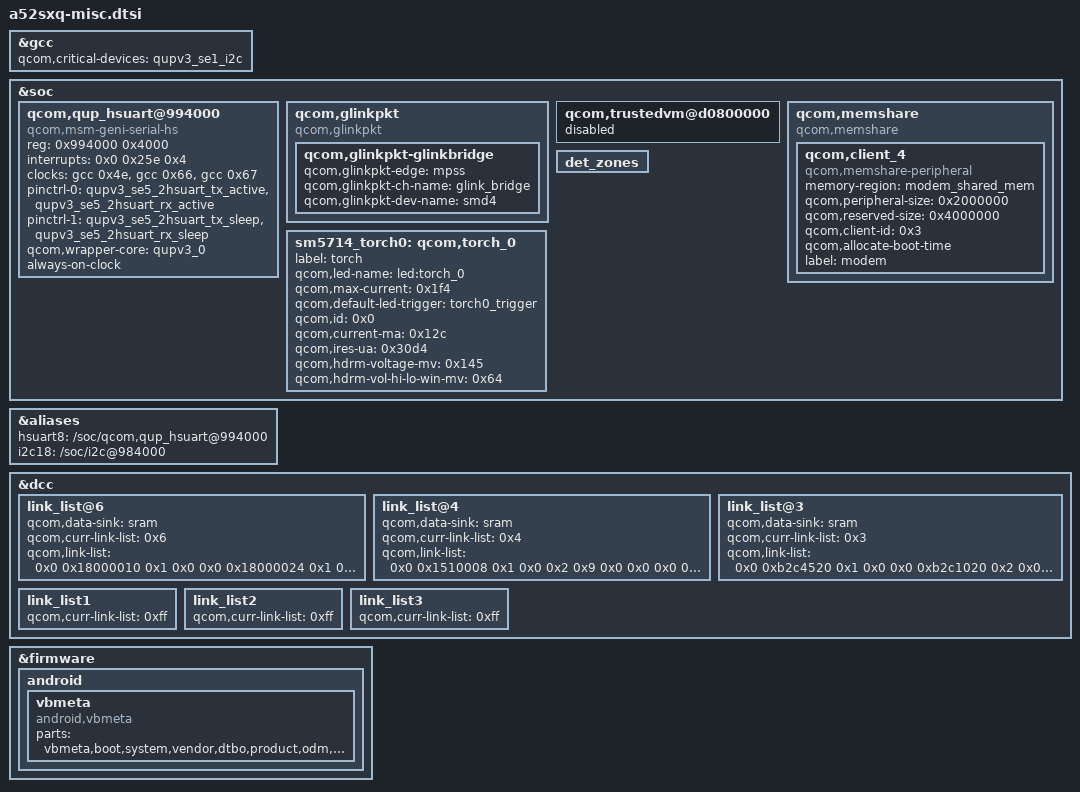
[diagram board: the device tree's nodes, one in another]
// SPDX-License-Identifier: GPL-2.0
/*
 * a52sxq board description for the Qualcomm 6.12 yupik base: misc
 * GENERATED by tools/gen.py from the phone's stock dtbo (5.4 bindings, values verbatim).
 * Do not edit: hand-written 6.12 changes live in a52sxq-bsp612-fixups.dtsi.
 */

&gcc {
	qcom,critical-devices = <&qupv3_se1_i2c>;
};

&soc {

	qcom,qup_hsuart@994000 {
		compatible = "qcom,msm-geni-serial-hs";
		reg = <0x994000 0x4000>;
		reg-names = "se_phys";
		interrupts = <0x0 0x25e 0x4>;
		clock-names = "se-clk", "m-ahb", "s-ahb";
		clocks = <&gcc 0x4e &gcc 0x66 &gcc 0x67>;
		pinctrl-names = "default", "sleep";
		pinctrl-0 = <&qupv3_se5_2hsuart_tx_active &qupv3_se5_2hsuart_rx_active>;
		pinctrl-1 = <&qupv3_se5_2hsuart_tx_sleep &qupv3_se5_2hsuart_rx_sleep>;
		qcom,wrapper-core = <&qupv3_0>;
		always-on-clock;
		status = "ok";
	};

	qcom,glinkpkt {
		compatible = "qcom,glinkpkt";

		qcom,glinkpkt-glinkbridge {
			qcom,glinkpkt-edge = "mpss";
			qcom,glinkpkt-ch-name = "glink_bridge";
			qcom,glinkpkt-dev-name = "smd4";
		};
	};

	qcom,trustedvm@d0800000 {
		status = "disabled";
	};

	qcom,memshare {
		compatible = "qcom,memshare";

		qcom,client_4 {
			compatible = "qcom,memshare-peripheral";
			memory-region = <&modem_shared_mem>;
			qcom,peripheral-size = <0x2000000>;
			qcom,reserved-size = <0x4000000>;
			qcom,client-id = <0x3>;
			qcom,allocate-boot-time;
			label = "modem";
		};
	};

	det_zones: det_zones {
		#list-det-cells = <0x2>;
	};

	sm5714_torch0: qcom,torch_0 {
		label = "torch";
		qcom,led-name = "led:torch_0";
		qcom,max-current = <0x1f4>;
		qcom,default-led-trigger = "torch0_trigger";
		qcom,id = <0x0>;
		qcom,current-ma = <0x12c>;
		qcom,ires-ua = <0x30d4>;
		qcom,hdrm-voltage-mv = <0x145>;
		qcom,hdrm-vol-hi-lo-win-mv = <0x64>;
	};
};

&aliases {
	hsuart8 = "/soc/qcom,qup_hsuart@994000";
	i2c18 = "/soc/i2c@984000";
};

&dcc {

	link_list@6 {
		qcom,data-sink = "sram";
		qcom,curr-link-list = <0x6>;
		qcom,link-list = <0x0 0x18000010 0x1 0x0 0x0 0x18000024 0x1 0x0 0x0 0x18000038 0x6 0x0 0x0 0x18010010 0x1 0x0 0x0 0x18010024 0x1 0x0 0x0 0x18010038 0x6 0x0 0x0 0x18020010 0x1 0x0 0x0 0x18020024 0x1 0x0 0x0 0x18020038 0x6 0x0 0x0 0x18030010 0x1 0x0 0x0 0x18030024 0x1 0x0 0x0 0x18030038 0x6 0x0 0x0 0x18040010 0x1 0x0 0x0 0x18040024 0x1 0x0 0x0 0x18040038 0x6 0x0 0x0 0x18050010 0x1 0x0 0x0 0x18050024 0x1 0x0 0x0 0x18050038 0x6 0x0 0x0 0x18060010 0x1 0x0 0x0 0x18060024 0x1 0x0 0x0 0x18060038 0x6 0x0 0x0 0x18070010 0x1 0x0 0x0 0x18070024 0x1 0x0 0x0 0x18070038 0x6 0x0 0x0 0x18080010 0x1 0x0 0x0 0x18080024 0x1 0x0 0x0 0x18080038 0x6 0x0 0x0 0x1808006c 0x5 0x0 0x0 0x18080084 0x1 0x0 0x0 0x180800f4 0x1 0x0 0x0 0x180800f8 0x1 0x0 0x0 0x180800fc 0x1 0x0 0x0 0x18080100 0xc 0x0 0x0 0x18080130 0x3 0x0 0x0 0x18080158 0x1 0x0 0x0 0x1808015c 0x1 0x0 0x0 0x18080160 0x1 0x0 0x0 0x18080164 0x1 0x0 0x0 0x18080168 0x1 0x0 0x0 0x18080170 0x1 0x0 0x0 0x18080174 0x1 0x0 0x0 0x18080188 0x1 0x0 0x0 0x1808018c 0x1 0x0 0x0 0x18080190 0x1 0x0 0x0 0x18080194 0x1 0x0 0x0 0x18080198 0x1 0x0 0x0 0x180801ac 0x1 0x0 0x0 0x180801b0 0x4 0x0 0x0 0x180801c0 0x1 0x0 0x0 0x180801c8 0x1 0x0 0x0 0x180801f0 0x1 0x0 0x0 0x18598020 0x1 0x0 0x0 0x1859001c 0x1 0x0 0x0 0x18590020 0x1 0x0 0x0 0x1859002c 0x1 0x0 0x0 0x18590064 0x1 0x0 0x0 0x18590068 0x1 0x0 0x0 0x1859006c 0x1 0x0 0x0 0x18590070 0x3 0x0 0x0 0x1859008c 0x1 0x0 0x0 0x185900dc 0x1 0x0 0x0 0x185900e8 0x1 0x0 0x0 0x185900ec 0x1 0x0 0x0 0x185900f0 0x1 0x0 0x0 0x18590300 0x1 0x0 0x0 0x1859030c 0x1 0x0 0x0 0x18590320 0x1 0x0 0x0 0x1859034c 0x1 0x0 0x0 0x185903bc 0x1 0x0 0x0 0x185903c0 0x1 0x0 0x0 0x1859101c 0x1 0x0 0x0 0x18591020 0x1 0x0 0x0 0x1859102c 0x1 0x0 0x0 0x18591064 0x1 0x0 0x0 0x18591068 0x1 0x0 0x0 0x1859106c 0x1 0x0 0x0 0x18591070 0x1 0x0 0x0 0x18591074 0x1 0x0 0x0 0x18591078 0x1 0x0 0x0 0x1859108c 0x1 0x0 0x0 0x185910dc 0x1 0x0 0x0 0x185910e8 0x1 0x0 0x0 0x185910ec 0x1 0x0 0x0 0x185910f0 0x1 0x0 0x0 0x18591300 0x1 0x0 0x0 0x1859130c 0x1 0x0 0x0 0x18591320 0x1 0x0 0x0 0x1859134c 0x1 0x0 0x0 0x185913bc 0x1 0x0 0x0 0x185913c0 0x1 0x0 0x0 0x1859201c 0x1 0x0 0x0 0x18592020 0x1 0x0 0x0 0x1859202c 0x1 0x0 0x0 0x18592064 0x1 0x0 0x0 0x18592068 0x1 0x0 0x0 0x1859206c 0x1 0x0 0x0 0x18592070 0x1 0x0 0x0 0x18592074 0x1 0x0 0x0 0x18592078 0x1 0x0 0x0 0x1859208c 0x1 0x0 0x0 0x185920dc 0x1 0x0 0x0 0x185920e8 0x1 0x0 0x0 0x185920ec 0x1 0x0 0x0 0x185920f0 0x1 0x0 0x0 0x18592300 0x1 0x0 0x0 0x1859230c 0x1 0x0 0x0 0x18592320 0x1 0x0 0x0 0x1859234c 0x1 0x0 0x0 0x185923bc 0x1 0x0 0x0 0x185923c0 0x1 0x0 0x0 0x1859301c 0x1 0x0 0x0 0x18593020 0x1 0x0 0x0 0x18593064 0x1 0x0 0x0 0x18593068 0x1 0x0 0x0 0x1859306c 0x1 0x0 0x0 0x18593070 0x1 0x0 0x0 0x18593074 0x1 0x0 0x0 0x18593078 0x1 0x0 0x0 0x1859308c 0x1 0x0 0x0 0x185930dc 0x1 0x0 0x0 0x185930e8 0x1 0x0 0x0 0x185930ec 0x1 0x0 0x0 0x185930f0 0x1 0x0 0x0 0x18593300 0x1 0x0 0x0 0x1859330c 0x1 0x0 0x0 0x18593320 0x1 0x0 0x0 0x1859302c 0x1 0x0 0x0 0x1859334c 0x1 0x0 0x0 0x185933bc 0x1 0x0 0x0 0x185933c0 0x1 0x0 0x0 0x18300000 0x1 0x0 0x0 0x1830000c 0x1 0x0 0x0 0x18300018 0x1 0x0 0x0 0x17c21000 0x2 0x0 0x0 0x18393a84 0x2 0x0 0x0 0x183a3a84 0x2 0x0 0x0 0x18280000 0x2 0x0 0x0 0x18282000 0x2 0x0 0x0 0x18284000 0x2 0x0 0x0 0x18286000 0x2 0x0 0x0 0x18300000 0x1 0x0 0x0 0x18200400 0x3 0x0 0x0 0x18200038 0x1 0x0 0x0 0x18200040 0x1 0x0 0x0 0x18200048 0x1 0x0 0x0 0x18220038 0x1 0x0 0x0 0x18220040 0x1 0x0 0x0 0x182200d0 0x1 0x0 0x0 0x18200030 0x1 0x0 0x0 0x18200010 0x1 0x0 0x0 0x610100 0xb 0x0 0x0 0x18000058 0x1 0x0 0x0 0x1800005c 0x1 0x0 0x0 0x18000060 0x1 0x0 0x0 0x18000064 0x1 0x0 0x0 0x1800006c 0x1 0x0 0x0 0x180000f0 0x2 0x0 0x0 0x18010058 0x1 0x0 0x0 0x1801005c 0x1 0x0 0x0 0x18010060 0x1 0x0 0x0 0x18010064 0x1 0x0 0x0 0x1801006c 0x1 0x0 0x0 0x180100f0 0x2 0x0 0x0 0x18020058 0x1 0x0 0x0 0x1802005c 0x1 0x0 0x0 0x18020060 0x1 0x0 0x0 0x18020064 0x1 0x0 0x0 0x1802006c 0x1 0x0 0x0 0x180200f0 0x2 0x0 0x0 0x18030058 0x1 0x0 0x0 0x1803005c 0x1 0x0 0x0 0x18030060 0x1 0x0 0x0 0x18030064 0x1 0x0 0x0 0x1803006c 0x1 0x0 0x0 0x180300f0 0x2 0x0 0x0 0x18040058 0x1 0x0 0x0 0x1804005c 0x1 0x0 0x0 0x18040060 0x1 0x0 0x0 0x18040064 0x1 0x0 0x0 0x1804006c 0x1 0x0 0x0 0x180400f0 0x2 0x0 0x0 0x18050058 0x1 0x0 0x0 0x1805005c 0x1 0x0 0x0 0x18050060 0x1 0x0 0x0 0x18050064 0x1 0x0 0x0 0x1805006c 0x1 0x0 0x0 0x180500f0 0x2 0x0 0x0 0x18060058 0x1 0x0 0x0 0x1806005c 0x1 0x0 0x0 0x18060060 0x1 0x0 0x0 0x18060064 0x1 0x0 0x0 0x1806006c 0x1 0x0 0x0 0x180600f0 0x2 0x0 0x0 0x18070058 0x1 0x0 0x0 0x1807005c 0x1 0x0 0x0 0x18070060 0x1 0x0 0x0 0x18070064 0x1 0x0 0x0 0x1807006c 0x1 0x0 0x0 0x180700f0 0x2 0x0 0x0 0x18101908 0x1 0x0 0x0 0x18101c18 0x1 0x0 0x0 0x18390810 0x1 0x0 0x0 0x18390c50 0x1 0x0 0x0 0x18390814 0x1 0x0 0x0 0x18390c54 0x1 0x0 0x0 0x18390818 0x1 0x0 0x0 0x18390c58 0x1 0x0 0x0 0x18393a84 0x2 0x0 0x0 0x18100908 0x1 0x0 0x0 0x18100c18 0x1 0x0 0x0 0x183a0810 0x1 0x0 0x0 0x183a0c50 0x1 0x0 0x0 0x183a0814 0x1 0x0 0x0 0x183a0c54 0x1 0x0 0x0 0x183a0818 0x1 0x0 0x0 0x183a0c58 0x1 0x0 0x0 0x183a3a84 0x2 0x0 0x0 0x18393500 0x1 0x0 0x0 0x18393580 0x1 0x0 0x0 0x183a3500 0x1 0x0 0x0 0x183a3580 0x1 0x0 0x0 0x18282000 0x4 0x0 0x0 0x18282028 0x1 0x0 0x0 0x18282038 0x1 0x0 0x0 0x18282080 0x5 0x0 0x0 0x18286000 0x4 0x0 0x0 0x18286028 0x1 0x0 0x0 0x18286038 0x1 0x0 0x0 0x18286080 0x5 0x0 0x0 0xc201244 0x1 0x0 0x0 0xc202244 0x1 0x0 0x0 0x18300000 0x1 0x0 0x0 0x1829208c 0x1 0x0 0x0 0x18292098 0x1 0x0 0x0 0x18292098 0x1 0x0 0x0 0x1829608c 0x1 0x0 0x0 0x18296098 0x1 0x0 0x0 0x18296098 0x1 0x0 0x0 0x784184 0x1 0x0 0x0 0x9103008 0x1 0x0 0x2 0x5 0x0 0x0 0x0 0x9103010 0x1 0x0 0x0 0x9103014 0x1 0x0 0x2 0x1 0x0 0x0 0x0 0x9103408 0x1 0x0 0x2 0x5 0x0 0x0 0x0 0x9103410 0x1 0x0 0x0 0x9103414 0x1 0x0 0x2 0x1 0x0 0x0 0x0 0x9143008 0x1 0x0 0x2 0x5 0x0 0x0 0x0 0x9143010 0x1 0x0 0x0 0x9143014 0x1 0x0 0x2 0x1 0x0 0x0 0x0 0x9143408 0x1 0x0 0x2 0x5 0x0 0x0 0x0 0x9143410 0x1 0x0 0x0 0x9143414 0x1 0x0 0x2 0x1 0x0 0x0 0x0 0x91b0008 0x1 0x0 0x2 0x3 0x0 0x0 0x0 0x91b0010 0x1 0x0 0x0 0x91b0014 0x1 0x0 0x2 0x1 0x0 0x0 0x0 0x91b1008 0x1 0x0 0x2 0x10 0x0 0x0 0x0 0x91b1010 0x1 0x0 0x0 0x91b1014 0x1 0x0 0x2 0x1 0x0 0x0 0x0 0x9101808 0x1 0x0 0x0 0x910180c 0x1 0x0 0x1 0x9101828 0x1 0x1 0x2 0x41 0x0 0x0 0x0 0x9101810 0x1 0x0 0x0 0x9101814 0x1 0x0 0x0 0x9101818 0x1 0x0 0x0 0x910181c 0x1 0x0 0x2 0x1 0x0 0x0 0x0 0x9141808 0x1 0x0 0x0 0x914180c 0x1 0x0 0x1 0x9141828 0x1 0x1 0x2 0x41 0x0 0x0 0x0 0x9141810 0x1 0x0 0x0 0x9141814 0x1 0x0 0x0 0x9141818 0x1 0x0 0x0 0x914181c 0x1 0x0 0x2 0x1 0x0 0x0 0x0 0x91a8008 0x1 0x0 0x0 0x91a800c 0x1 0x0 0x1 0x91a8028 0x1 0x1 0x2 0x11 0x0 0x0 0x0 0x91a8010 0x1 0x0 0x0 0x91a8014 0x1 0x0 0x0 0x91a8018 0x1 0x0 0x0 0x91a801c 0x1 0x0 0x2 0x1 0x0 0x0 0x0 0x91a8808 0x1 0x0 0x0 0x91a880c 0x1 0x0 0x1 0x91a8828 0x1 0x1 0x2 0x11 0x0 0x0 0x0 0x91a8810 0x1 0x0 0x0 0x91a8814 0x1 0x0 0x0 0x91a8818 0x1 0x0 0x0 0x91a881c 0x1 0x0 0x2 0x1 0x0 0x0 0x0 0x9100000 0x1 0x0 0x0 0x9100008 0x1 0x0 0x0 0x910000c 0x1 0x0 0x0 0x9140000 0x1 0x0 0x0 0x9140008 0x1 0x0 0x0 0x914000c 0x1 0x0 0x0 0x9180000 0x1 0x0 0x0 0x9180008 0x1 0x0 0x0 0x918000c 0x1 0x0 0x0 0x9180404 0x1 0x0 0x0 0x9180408 0x1 0x0 0x0 0x918040c 0x1 0x0 0x0 0x9181010 0x1 0x0 0x0 0x9181020 0x8 0x0 0x0 0x91e1048 0x1 0x0 0x0 0x9121010 0x1 0x0 0x0 0x9122010 0x1 0x0 0x0 0x9123010 0x1 0x0 0x0 0x9125010 0x1 0x0 0x0 0x9161010 0x1 0x0 0x0 0x9162010 0x1 0x0 0x0 0x9163010 0x1 0x0 0x0 0x9165010 0x1 0x0 0x0 0x91cf010 0x1 0x0 0x0 0x91d0010 0x1 0x0 0x0 0x91d1010 0x1 0x0 0x0 0x91d2010 0x1 0x0 0x0 0x91d3010 0x1 0x0 0x0 0x91d4010 0x1 0x0 0x0 0x91d5010 0x1 0x0 0x0 0x91d6010 0x1 0x0 0x0 0x91d7010 0x1 0x0 0x0 0x9101408 0x1 0x0 0x0 0x9141410 0x1 0x0 0x0 0x9100810 0x1 0x0 0x0 0x9140810 0x1 0x0 0x0 0x9100820 0x1 0x0 0x0 0x9140820 0x1 0x0 0x0 0x9100828 0x1 0x0 0x0 0x910082c 0x1 0x0 0x0 0x9140828 0x1 0x0 0x0 0x914082c 0x1 0x0 0x0 0xc222004 0x1 0x0 0x0 0xc263014 0x1 0x0 0x0 0xc2630e0 0x1 0x0 0x0 0xc2630ec 0x1 0x0 0x0 0xc2630a0 0x10 0x0 0x0 0xc2630e8 0x1 0x0 0x0 0xc26313c 0x1 0x0 0x0 0xc223004 0x1 0x0 0x0 0xc265014 0x1 0x0 0x0 0xc2650e0 0x1 0x0 0x0 0xc2650ec 0x1 0x0 0x0 0xc2650a0 0x10 0x0 0x0 0xc2650e8 0x1 0x0 0x0 0xc26513c 0x1 0x0 0x0 0xc410000 0x1 0x0 0x0 0xc40af04 0x1 0x0 0x0 0xc40af10 0x1 0x0 0x0 0xc40a000 0x1 0x0 0x0 0xc40a018 0x1 0x0 0x0 0xc40a028 0x1 0x0 0x0 0xc40a02c 0x1 0x0 0x0 0xc40a100 0x1 0x0 0x0 0xc2a22fc 0x1 0x0 0x0 0xc2a2300 0x1 0x0 0x0 0xc2a2304 0x1 0x0 0x0 0xc440200 0x1 0x0 0x0 0xc440204 0x1 0x0 0x0 0xc442200 0x1 0x0 0x0 0xc442204 0x1 0x0 0x0 0xc442208 0x1 0x0 0x0 0xc44220c 0x1 0x0 0x0 0x3d9100c 0x1 0x0 0x0 0x3d91010 0x2 0x0 0x0 0x3d9106c 0x3 0x0 0x0 0x3d91004 0x1 0x0 0x0 0x3d91054 0x3 0x0 0x0 0x3d91060 0x2 0x0 0x0 0x3d91070 0x2 0x0 0x0 0x3d91080 0x3 0x0 0x0 0x3d91078 0x2 0x0 0x0 0x3d9108c 0x1 0x0 0x0 0x3d91090 0x1 0x0 0x0 0x3d91098 0x2 0x0 0x0 0x3d910a4 0x2 0x0 0x0 0x3d910f0 0x2 0x0 0x0 0x3d91100 0x1 0x0 0x0 0x3d91118 0x1 0x0 0x0 0x3d91164 0x2 0x0 0x0 0x3d91170 0x1 0x0 0x0 0x3d91178 0x1 0x0 0x0 0x3d91204 0x1 0x0 0x0 0x3d9120c 0x1 0x0 0x0 0x3d98024 0x1 0x0 0x0 0x3d9802c 0x1 0x0 0x0 0x3d98030 0x1 0x0 0x0 0x3d92000 0x2 0x0 0x0 0x3d93000 0x2 0x0 0x0 0x3d95000 0x2 0x0 0x0 0x3d96000 0x2 0x0 0x0 0x3d97000 0x2 0x0 0x0 0x119000 0x1 0x0 0x0 0x11903c 0x1 0x0 0x0 0x171004 0x2 0x0 0x0 0x17100c 0x1 0x0 0x0 0x171014 0x1 0x0 0x0 0x171018 0x1 0x0 0x0 0x171154 0x1 0x0 0x0 0x171158 0x1 0x0 0x0 0x17115c 0x1 0x0 0x0 0x17a04c 0x1 0x0 0x0 0x17b000 0x1 0x0 0x0 0x17b03c 0x1 0x0 0x0 0x17c000 0x1 0x0 0x0 0x17c03c 0x1 0x0 0x0 0x17d000 0x1 0x0 0x0 0x17d03c 0x1 0x0 0x0 0x17e000 0x1 0x0 0x0 0x17e03c 0x1 0x0 0x0 0x187000 0x1 0x0 0x0 0x18703c 0x1 0x0 0x0 0x3d91534 0x1 0x0 0x0 0x3d002b4 0x1 0x0 0x0 0x3d00410 0x2 0x0 0x0 0x3d00818 0x1 0x0 0x0 0x3d7e220 0x2 0x0 0x0 0x1680000 0x1 0x0 0x0 0x1680008 0x1 0x0 0x0 0x1680010 0x1 0x0 0x0 0x1680020 0x8 0x0 0x0 0x1680248 0x1 0x0 0x0 0x1680b00 0x6 0x0 0x0 0x16e4008 0x1 0x0 0x2 0x4 0x0 0x0 0x0 0x16e4010 0x1 0x0 0x0 0x16e4014 0x1 0x0 0x2 0x1 0x0 0x0 0x0 0x1706208 0x1 0x0 0x2 0x4 0x0 0x0 0x0 0x1706210 0x1 0x0 0x0 0x1706214 0x1 0x0 0x2 0x1 0x0 0x0 0x0 0x16e0000 0x1 0x0 0x0 0x16e0010 0x1 0x0 0x0 0x16e0008 0x1 0x0 0x0 0x16e0020 0x8 0x0 0x0 0x16e5048 0x1 0x0 0x0 0x16e5248 0x1 0x0 0x0 0x16e5448 0x1 0x0 0x0 0x16e5100 0x5 0x0 0x0 0x16e5300 0x2 0x0 0x0 0x16e5500 0x2 0x0 0x0 0x1700000 0x1 0x0 0x0 0x1700008 0x1 0x0 0x0 0x1700010 0x1 0x0 0x0 0x1700020 0x8 0x0 0x0 0x170b100 0x5 0x0 0x0 0x170b048 0x1 0x0 0x0 0x100000 0xf 0x0 0x0 0x101000 0xf 0x0 0x0 0x176000 0xf 0x0 0x0 0x174000 0xf 0x0 0x0 0x113000 0xf 0x0 0x0 0x11a000 0xf 0x0 0x0 0x11c000 0xf 0x0 0x0 0x11c048 0x3 0x0 0x0 0x11e000 0xf 0x0 0x0 0x10401c 0x1 0x0 0x0 0x105074 0x1 0x0 0x0 0x183024 0x1 0x0 0x0 0x109050 0x1 0x0 0x0 0x123020 0x1 0x0 0x0 0x117024 0x1 0x0 0x0 0x117154 0x1 0x0 0x0 0x117284 0x1 0x0 0x0 0x1173b4 0x1 0x0 0x0 0x1174e4 0x1 0x0 0x0 0x117614 0x1 0x0 0x0 0x117744 0x1 0x0 0x0 0x117874 0x1 0x0 0x0 0x118024 0x1 0x0 0x0 0x118154 0x1 0x0 0x0 0x118284 0x1 0x0 0x0 0x1183b4 0x1 0x0 0x0 0x1184e4 0x1 0x0 0x0 0x118614 0x1 0x0 0x0 0x118744 0x1 0x0 0x0 0x118874 0x1 0x0 0x0 0x129020 0x1 0x0 0x0 0x11d020 0x1 0x0 0x0 0x134024 0x1 0x0 0x0 0x141024 0x1 0x0 0x0 0x14415c 0x1 0x0 0x0 0x14504c 0x1 0x0 0x0 0x18903c 0x1 0x0 0x0 0x151000 0x1 0x0 0x0 0x151008 0x1 0x0 0x0 0x151010 0x1 0x0 0x0 0x152000 0x1 0x0 0x0 0x152008 0x1 0x0 0x0 0x152010 0x1 0x0 0x0 0x153020 0x1 0x0 0x0 0x153028 0x1 0x0 0x0 0x153030 0x1 0x0 0x0 0x155000 0x1 0x0 0x0 0x155008 0x1 0x0 0x0 0x155010 0x1 0x0 0x0 0x15b000 0x1 0x0 0x0 0x15b008 0x1 0x0 0x0 0x15b010 0x1 0x0 0x0 0x157000 0x1 0x0 0x0 0x157008 0x1 0x0 0x0 0x157010 0x1 0x0 0x0 0x135020 0x1 0x0 0x0 0x135028 0x1 0x0 0x0 0x135030 0x1 0x0 0x0 0x156000 0x1 0x0 0x0 0x156008 0x1 0x0 0x0 0x156010 0x1 0x0 0x0 0x15a000 0x1 0x0 0x0 0x15a008 0x1 0x0 0x0 0x15a010 0x1 0x0 0x0 0x190004 0x1 0x0 0x0 0x109008 0x1 0x0 0x0 0x190010 0x1 0x0 0x0 0x190020 0x1 0x0 0x0 0x190028 0x1 0x0 0x0 0x109010 0x1 0x0 0x0 0x109018 0x1 0x0 0x0 0x109018 0x1 0x0 0x0 0x109020 0x1 0x0 0x0 0x18d080 0x1 0x0 0x0 0x145014 0x1 0x0 0x0 0x14501c 0x1 0x0 0x0 0x183004 0x1 0x0 0x0 0x183008 0x1 0x0 0x0 0x183140 0x1 0x0 0x0 0x171158 0x2 0x0 0x0 0x109004 0x3 0x0 0x0 0x109160 0x1 0x0 0x0 0x109468 0x1 0x0 0x0 0x10f004 0x3 0x0 0x0 0x145000 0x3 0x0 0x0 0x16b004 0x3 0x0 0x0 0x18d004 0x3 0x0 0x0 0x177004 0x3 0x0 0x0 0x189004 0x3 0x0 0x0 0x153000 0x9 0x0 0x0 0x135000 0x9 0x0 0x0 0x106100 0x1 0x0 0x0 0x147004 0x1 0x0 0x0 0x17b000 0x1 0x0 0x0 0x17b004 0x1 0x0 0x0 0x17b008 0x1 0x0 0x0 0x17b00c 0x1 0x0 0x0 0x17b010 0x1 0x0 0x0 0x17b014 0x1 0x0 0x0 0x17b018 0x1 0x0 0x0 0x17b01c 0x1 0x0 0x0 0x17b020 0x1 0x0 0x0 0x17b024 0x1 0x0 0x0 0x17b028 0x1 0x0 0x0 0x17b02c 0x1 0x0 0x0 0x17b03c 0x1 0x0 0x0 0x17b040 0x1 0x0 0x0 0x17b044 0x1 0x0 0x0 0x17b048 0x1 0x0 0x0 0x17b04c 0x1 0x0 0x0 0x17b050 0x1 0x0 0x0 0x17b054 0x1 0x0 0x0 0x17b058 0x1 0x0 0x0 0x17b05c 0x1 0x0 0x0 0x17b060 0x1 0x0 0x0 0x17b064 0x1 0x0 0x0 0x17b068 0x1 0x0 0x0 0x17c000 0x1 0x0 0x0 0x17c004 0x1 0x0 0x0 0x17c008 0x1 0x0 0x0 0x17c00c 0x1 0x0 0x0 0x17c010 0x1 0x0 0x0 0x17c014 0x1 0x0 0x0 0x17c018 0x1 0x0 0x0 0x17c01c 0x1 0x0 0x0 0x17c020 0x1 0x0 0x0 0x17c024 0x1 0x0 0x0 0x17c028 0x1 0x0 0x0 0x17c02c 0x1 0x0 0x0 0x17c03c 0x1 0x0 0x0 0x17c040 0x1 0x0 0x0 0x17c044 0x1 0x0 0x0 0x17c048 0x1 0x0 0x0 0x17c04c 0x1 0x0 0x0 0x17c050 0x1 0x0 0x0 0x17c054 0x1 0x0 0x0 0x17c058 0x1 0x0 0x0 0x17c05c 0x1 0x0 0x0 0x17c060 0x1 0x0 0x0 0x17c064 0x1 0x0 0x0 0x17c068 0x1 0x0 0x0 0x153124 0x1 0x0 0x0 0x156124 0x1 0x0 0x0 0x1453a4 0x1 0x0 0x0 0x182884 0x1 0x0 0x0 0x145384 0x1 0x0 0x0 0xc2a0000 0xf 0x0 0x0 0xc2a1000 0xf 0x0 0x0 0x17101c 0x1 0x0 0x0 0x171020 0x1 0x0 0x0 0x14401c 0x1 0x0 0x0 0x144020 0x1 0x0 0x0 0x183010 0x1 0x0 0x0 0x183014 0x1 0x0 0x0 0x18a160 0x1 0x0 0x0 0x18a164 0x1 0x0 0x0 0x18a004 0x1 0x0 0x0 0x18a01c 0x1 0x0 0x0 0x18a020 0x1 0x0 0x0 0x18a024 0x1 0x0 0x0 0x19d004 0x1 0x0 0x0 0x19d008 0x1 0x0 0x0 0x196100 0x1 0x0 0x0 0x10003c 0x1 0x0 0x0 0x10103c 0x1 0x0 0x0 0x10203c 0x1 0x0 0x0 0x10303c 0x1 0x0 0x0 0x11303c 0x1 0x0 0x0 0x11a03c 0x1 0x0 0x0 0x11c03c 0x1 0x0 0x0 0x17403c 0x1 0x0 0x0 0x17603c 0x1 0x0 0x0 0x11e03c 0x1 0x0 0x0 0xbbf0004 0xc 0x0 0x0 0xbbf0800 0xc 0x0 0x0 0xbbf0004 0xc 0x0 0x0 0xbbf0800 0xc 0x0>;
	};

	link_list@4 {
		qcom,data-sink = "sram";
		qcom,curr-link-list = <0x4>;
		qcom,link-list = <0x0 0x1510008 0x1 0x0 0x2 0x9 0x0 0x0 0x0 0x151d010 0x1 0x0 0x0 0x151d014 0x1 0x0 0x2 0x1 0x0 0x0 0x2 0x9 0x0 0x0 0x0 0x1506010 0x1 0x0 0x0 0x1506014 0x1 0x0 0x2 0x1 0x0 0x0 0x0 0x151d208 0x1 0x0 0x0 0x1507008 0x1 0x0 0x2 0x2 0x0 0x0 0x0 0x151d210 0x1 0x0 0x0 0x151d214 0x1 0x0 0x2 0x1 0x0 0x0 0x2 0x2 0x0 0x0 0x0 0x1507010 0x1 0x0 0x0 0x1507014 0x1 0x0 0x2 0x1 0x0 0x0 0x0 0x151d308 0x1 0x0 0x0 0x1509008 0x1 0x0 0x2 0x3 0x0 0x0 0x0 0x1509010 0x1 0x0 0x0 0x1509014 0x1 0x0 0x2 0x1 0x0 0x0 0x2 0x3 0x0 0x0 0x0 0x151d310 0x1 0x0 0x0 0x151d314 0x1 0x0 0x2 0x1 0x0 0x0 0x0 0x1514008 0x1 0x0 0x2 0x3 0x0 0x0 0x0 0x1514010 0x1 0x0 0x2 0x1 0x0 0x0 0x0 0x1500000 0x1 0x0 0x0 0x1510000 0x1 0x0 0x0 0x1500010 0x1 0x0 0x0 0x1510010 0x1 0x0 0x0 0x1500020 0x8 0x0 0x0 0x1510020 0x8 0x0 0x0 0x1511048 0x1 0x0 0x0 0x1501048 0x2 0x0 0x0 0x1501058 0x1 0x0 0x0 0x1501248 0x1 0x0 0x0 0x1511248 0x1 0x0 0x0 0x1501248 0x1 0x0 0x0 0x1511b00 0x1 0x0 0x0 0x151e100 0x1 0x0 0x0 0x150b100 0x1 0x0 0x0 0xec80004 0x1 0x0 0x0 0xec80058 0x1 0x0 0x0 0xec80060 0x8 0x0 0x0 0xec800a0 0x8 0x0 0x0 0xec800c0 0x10 0x0 0x0 0xec80100 0x10 0x0 0x0 0x634008 0x1 0x0 0x0 0x634f00 0x8 0x0 0x0 0x635560 0x1 0x0 0x0 0x635570 0x1 0x0 0x0 0x635580 0x1 0x0 0x0 0x635590 0x1 0x0 0x0 0x6355a0 0x4 0x0 0x0 0x635600 0x1 0x0 0x0 0x635610 0x1 0x0 0x0 0x636008 0x1 0x0 0x0 0x636f00 0x8 0x0 0x0 0x637560 0x1 0x0 0x0 0x637570 0x1 0x0 0x0 0x637580 0x1 0x0 0x0 0x637590 0x1 0x0 0x0 0x6375a0 0x4 0x0 0x0 0x637600 0x1 0x0 0x0 0x637610 0x1 0x0 0x0 0x18370220 0x2 0x0 0x0 0x183702a0 0x2 0x0 0x0 0x183704a0 0xc 0x0 0x0 0x18370520 0x1 0x0 0x0 0x18370588 0x1 0x0 0x0 0x18370d10 0xc 0x0 0x0 0x18370f90 0xa 0x0 0x0 0x18371010 0xa 0x0 0x0 0x18371a10 0x8 0x0 0x0 0x183784a0 0xc 0x0 0x0 0x18378520 0x1 0x0 0x0 0x18378588 0x1 0x0 0x0 0x18378d10 0x8 0x0 0x0 0x18378f90 0x6 0x0 0x0 0x18379010 0x6 0x0 0x0 0x18379a10 0x4 0x0 0x0 0xa310220 0x3 0x0 0x0 0xa3102a0 0x3 0x0 0x0 0xa3104a0 0x6 0x0 0x0 0xa310520 0x1 0x0 0x0 0xa310588 0x1 0x0 0x0 0xa310d10 0x8 0x0 0x0 0xa310f90 0x6 0x0 0x0 0xa311010 0x6 0x0 0x0 0xa311a10 0x3 0x0 0x0 0x17a00104 0x1d 0x0 0x0 0x17a00204 0x1d 0x0 0x0 0x1741008 0x1 0x0 0x2 0x9 0x0 0x0 0x0 0x1741010 0x1 0x0 0x0 0x1741014 0x1 0x0 0x2 0x1 0x0 0x0 0x0 0x1740000 0x1 0x0 0x0 0x1740008 0x1 0x0 0x0 0x1740010 0x1 0x0 0x0 0x1740020 0x8 0x0 0x0 0x174b048 0x1 0x0 0x0 0x174b100 0x8 0x0 0x0 0x90e0000 0x1 0x0 0x0 0x90e0008 0x1 0x0 0x0 0x90e0010 0x1 0x0 0x0 0x90e0020 0x8 0x0 0x0 0x90e0248 0x1 0x0 0x0 0x90e3100 0x1 0x0 0x0 0x90e4100 0x7 0x0 0x0 0x1750010 0x1 0x0 0x0 0x1750190 0x1 0x0 0x0 0x1751010 0x1 0x0 0x0 0x1752010 0x1 0x0 0x0 0x1754010 0x1 0x0 0x0 0x1755010 0x1 0x0 0x0 0x1756010 0x1 0x0 0x0 0x1758010 0x1 0x0 0x0 0x1758090 0x1 0x0 0x0 0x1759010 0x1 0x0 0x0 0x175a010 0x1 0x0 0x0 0x175c010 0x1 0x0 0x0 0x175d010 0x1 0x0 0x0 0x175e010 0x1 0x0 0x0 0xb201020 0x2 0x0 0x0 0xb200010 0x4 0x0 0x0 0xb220010 0x4 0x0 0x0 0xb200900 0x4 0x0 0x0 0xb220900 0x4 0x0 0x0 0xb201030 0x1 0x0 0x0 0xb201204 0x1 0x0 0x0 0xb201218 0x1 0x0 0x0 0xb20122c 0x1 0x0 0x0 0xb201240 0x1 0x0 0x0 0xb201254 0x1 0x0 0x0 0xb201208 0x1 0x0 0x0 0xb20121c 0x1 0x0 0x0 0xb201230 0x1 0x0 0x0 0xb201244 0x1 0x0 0x0 0xb201258 0x1 0x0 0x0 0xb204510 0x1 0x0 0x0 0xb204514 0x1 0x0 0x0 0xb204520 0x1 0x0 0x0 0xb211024 0x1 0x0 0x0 0xb221024 0x1 0x0 0x0 0xb231024 0x1 0x0 0x0 0x18220010 0x1 0x0 0x0 0x18220030 0x1 0x0 0x0 0x182200d0 0x1 0x0 0x0 0x18220408 0x1 0x0 0x0 0x18230408 0x1 0x0 0x0 0x17e00434 0x1 0x0 0x0 0x17e0043c 0x2 0x0 0x0 0x17c00038 0x2 0x0 0x0 0x17c00438 0x1 0x0 0x0 0x17e0041c 0x1 0x0 0x0 0x17e00420 0x1 0x0 0x0 0x17e00404 0x1 0x0 0x0 0xc220000 0x2 0x0 0x0 0xc230000 0x6 0x0 0x0 0xc260008 0x1 0x0 0x0 0x18598014 0x1 0x0 0x0 0x4d8634 0x1 0x0 0x0 0x4d8834 0x1 0x0 0x0 0x418620 0x1 0x0 0x0 0x418820 0x1 0x0 0x0 0x9084208 0x1 0x0 0x0 0x9084204 0x1 0x0 0x0 0x9084108 0x1 0x0 0x0 0x90841c0 0x1 0x0 0x0 0x10c034 0x1 0x0 0x0 0x10c038 0x1 0x0 0x0 0x144018 0x1 0x0 0x1 0x90841c0 0x1 0x0 0x1 0x10c034 0x1 0x0 0x1 0x10c038 0x1 0x0 0x1 0x144018 0x1 0x0 0x0 0x9050078 0x1 0x0 0x0 0x9050110 0x8 0x0 0x0 0x9080058 0x2 0x0 0x0 0x90800c8 0x1 0x0 0x0 0x90800d4 0x1 0x0 0x0 0x90800e0 0x1 0x0 0x0 0x90800fc 0x1 0x0 0x0 0x9084030 0x1 0x0 0x0 0x9084038 0x2 0x0 0x0 0x90840e4 0x1 0x0 0x0 0x90840f4 0x1 0x0 0x0 0x9084104 0x2 0x0 0x0 0x9084198 0x1 0x0 0x0 0x9084804 0x1 0x0 0x0 0x908480c 0x1 0x0 0x0 0x9084844 0x1 0x0 0x0 0x9084850 0x2 0x0 0x0 0x9084860 0x3 0x0 0x0 0x9084888 0x1 0x0 0x0 0x908488c 0x1 0x0 0x0 0x908409c 0x1 0x0 0x0 0x90840a0 0x1 0x0 0x0 0x908426c 0x1 0x0 0x0 0x908439c 0x1 0x0 0x0 0x9085124 0x1 0x0 0x0 0x9085134 0x1 0x0 0x0 0x9085138 0x1 0x0 0x0 0x9084840 0x1 0x0 0x0 0x9084834 0x1 0x0 0x0 0x9085124 0x1 0x0 0x0 0x90ba280 0x1 0x0 0x0 0x90ba288 0x7 0x0 0x0 0x9258610 0x4 0x0 0x0 0x92d8610 0x4 0x0 0x0 0x9220344 0x8 0x0 0x0 0x9220370 0x6 0x0 0x0 0x9220480 0x1 0x0 0x0 0x9222400 0x1 0x0 0x0 0x922240c 0x1 0x0 0x0 0x9223214 0x2 0x0 0x0 0x9223220 0x3 0x0 0x0 0x9223308 0x1 0x0 0x0 0x9223318 0x1 0x0 0x0 0x9232100 0x1 0x0 0x0 0x9236040 0x6 0x0 0x0 0x92360b0 0x1 0x0 0x0 0x923a004 0x4 0x0 0x0 0x923e030 0x2 0x0 0x0 0x9241000 0x1 0x0 0x0 0x9242028 0x1 0x0 0x0 0x9242044 0x3 0x0 0x0 0x9242070 0x1 0x0 0x0 0x9248030 0x1 0x0 0x0 0x9248048 0x8 0x0 0x0 0x9238030 0x1 0x0 0x0 0x9238060 0x1 0x0 0x0 0x9238064 0x1 0x0 0x0 0x9238074 0x1 0x0 0x0 0x9238088 0x1 0x0 0x0 0x92380a0 0x1 0x0 0x0 0x92380b0 0x1 0x0 0x0 0x92a0344 0x8 0x0 0x0 0x92a0370 0x6 0x0 0x0 0x92a0480 0x1 0x0 0x0 0x92a2400 0x1 0x0 0x0 0x92a240c 0x1 0x0 0x0 0x92a3214 0x2 0x0 0x0 0x92a3220 0x3 0x0 0x0 0x92a3308 0x1 0x0 0x0 0x92a3318 0x1 0x0 0x0 0x92b2100 0x1 0x0 0x0 0x92b6040 0x6 0x0 0x0 0x92b60b0 0x1 0x0 0x0 0x92ba004 0x4 0x0 0x0 0x92be030 0x2 0x0 0x0 0x92c1000 0x1 0x0 0x0 0x92c2028 0x1 0x0 0x0 0x92c2044 0x3 0x0 0x0 0x92c2070 0x1 0x0 0x0 0x92c8030 0x1 0x0 0x0 0x92c8048 0x8 0x0 0x0 0x92b8030 0x1 0x0 0x0 0x92b8060 0x1 0x0 0x0 0x92b8064 0x1 0x0 0x0 0x92b8074 0x1 0x0 0x0 0x92b8088 0x1 0x0 0x0 0x92b80a0 0x1 0x0 0x0 0x92b80b0 0x1 0x0 0x0 0x92c8064 0x1 0x0 0x0 0x9270080 0x1 0x0 0x0 0x9270310 0x1 0x0 0x0 0x9270400 0x1 0x0 0x0 0x9270410 0x6 0x0 0x0 0x9270430 0x1 0x0 0x0 0x9270440 0x1 0x0 0x0 0x9270448 0x1 0x0 0x0 0x92704a0 0x1 0x0 0x0 0x92704b0 0x1 0x0 0x0 0x92704b8 0x2 0x0 0x0 0x92704d0 0x2 0x0 0x0 0x9271400 0x1 0x0 0x0 0x9271408 0x1 0x0 0x0 0x927341c 0x1 0x0 0x0 0x9273420 0x1 0x0 0x0 0x92753b0 0x1 0x0 0x0 0x9275804 0x1 0x0 0x0 0x9275c18 0x2 0x0 0x0 0x9275c2c 0x1 0x0 0x0 0x9275c38 0x1 0x0 0x0 0x9276418 0x2 0x0 0x0 0x9279100 0x1 0x0 0x0 0x9279110 0x1 0x0 0x0 0x9279120 0x1 0x0 0x0 0x9279180 0x2 0x0 0x0 0x92f0080 0x1 0x0 0x0 0x92f0310 0x1 0x0 0x0 0x92f0400 0x1 0x0 0x0 0x92f0410 0x6 0x0 0x0 0x92f0430 0x1 0x0 0x0 0x92f0440 0x1 0x0 0x0 0x92f0448 0x1 0x0 0x0 0x92f04a0 0x1 0x0 0x0 0x92f04b0 0x1 0x0 0x0 0x92f04b8 0x2 0x0 0x0 0x92f04d0 0x2 0x0 0x0 0x92f1400 0x1 0x0 0x0 0x92f1408 0x1 0x0 0x0 0x92f341c 0x1 0x0 0x0 0x92f3420 0x1 0x0 0x0 0x92f53b0 0x1 0x0 0x0 0x92f5804 0x1 0x0 0x0 0x92f5c18 0x2 0x0 0x0 0x92f5c2c 0x1 0x0 0x0 0x92f5c38 0x1 0x0 0x0 0x92f6418 0x2 0x0 0x0 0x92f9100 0x1 0x0 0x0 0x92f9110 0x1 0x0 0x0 0x92f9120 0x1 0x0 0x0 0x92f9180 0x2 0x0 0x0 0x9260080 0x1 0x0 0x0 0x9260400 0x1 0x0 0x0 0x9260410 0x3 0x0 0x0 0x9260420 0x2 0x0 0x0 0x9260430 0x1 0x0 0x0 0x9260440 0x1 0x0 0x0 0x9260448 0x1 0x0 0x0 0x92604a0 0x1 0x0 0x0 0x92604b0 0x1 0x0 0x0 0x92604b8 0x2 0x0 0x0 0x92604d0 0x2 0x0 0x0 0x9261400 0x1 0x0 0x0 0x9263410 0x1 0x0 0x0 0x92653b0 0x1 0x0 0x0 0x9265804 0x1 0x0 0x0 0x9265b1c 0x1 0x0 0x0 0x9265b2c 0x1 0x0 0x0 0x9265b38 0x1 0x0 0x0 0x9269100 0x1 0x0 0x0 0x9269108 0x1 0x0 0x0 0x9269110 0x1 0x0 0x0 0x9269118 0x1 0x0 0x0 0x9269120 0x1 0x0 0x0 0x9269180 0x2 0x0 0x0 0x92e0080 0x1 0x0 0x0 0x92e0400 0x1 0x0 0x0 0x92e0410 0x3 0x0 0x0 0x92e0420 0x2 0x0 0x0 0x92e0430 0x1 0x0 0x0 0x92e0440 0x1 0x0 0x0 0x92e0448 0x1 0x0 0x0 0x92e04a0 0x1 0x0 0x0 0x92e04b0 0x1 0x0 0x0 0x92e04b8 0x2 0x0 0x0 0x92e04d0 0x2 0x0 0x0 0x92e1400 0x1 0x0 0x0 0x92e3410 0x1 0x0 0x0 0x92e53b0 0x1 0x0 0x0 0x92e5804 0x1 0x0 0x0 0x92e5b1c 0x1 0x0 0x0 0x92e5b2c 0x1 0x0 0x0 0x92e5b38 0x1 0x0 0x0 0x92e9100 0x1 0x0 0x0 0x92e9108 0x1 0x0 0x0 0x92e9110 0x1 0x0 0x0 0x92e9118 0x1 0x0 0x0 0x92e9120 0x1 0x0 0x0 0x92e9180 0x2 0x0 0x0 0x96b0868 0x1 0x0 0x0 0x96b0870 0x1 0x0 0x0 0x96b1004 0x1 0x0 0x0 0x96b100c 0x1 0x0 0x0 0x96b1014 0x1 0x0 0x0 0x96b1204 0x1 0x0 0x0 0x96b120c 0x1 0x0 0x0 0x96b1214 0x1 0x0 0x0 0x96b1504 0x1 0x0 0x0 0x96b150c 0x1 0x0 0x0 0x96b1514 0x1 0x0 0x0 0x96b1604 0x1 0x0 0x0 0x96b8100 0x1 0x0 0x0 0x96b813c 0x1 0x0 0x0 0x96b8500 0x1 0x0 0x0 0x96b853c 0x1 0x0 0x0 0x96b8a04 0x1 0x0 0x0 0x96b8a18 0x1 0x0 0x0 0x96b8ea8 0x1 0x0 0x0 0x96b9044 0x1 0x0 0x0 0x96b904c 0x1 0x0 0x0 0x96b9054 0x1 0x0 0x0 0x96b905c 0x1 0x0 0x0 0x96b910c 0x2 0x0 0x0 0x96b9204 0x1 0x0 0x0 0x96b920c 0x1 0x0 0x0 0x96b9238 0x1 0x0 0x0 0x96b9240 0x1 0x0 0x0 0x96b926c 0x1 0x0 0x0 0x96b9394 0x1 0x0 0x0 0x96b939c 0x1 0x0 0x0 0x96b9704 0x1 0x0 0x0 0x96b970c 0x1 0x0 0x0 0x96f0868 0x1 0x0 0x0 0x96f0870 0x1 0x0 0x0 0x96f1004 0x1 0x0 0x0 0x96f100c 0x1 0x0 0x0 0x96f1014 0x1 0x0 0x0 0x96f1204 0x1 0x0 0x0 0x96f120c 0x1 0x0 0x0 0x96f1214 0x1 0x0 0x0 0x96f1504 0x1 0x0 0x0 0x96f150c 0x1 0x0 0x0 0x96f1514 0x1 0x0 0x0 0x96f1604 0x1 0x0 0x0 0x96f8100 0x1 0x0 0x0 0x96f813c 0x1 0x0 0x0 0x96f8500 0x1 0x0 0x0 0x96f853c 0x1 0x0 0x0 0x96f8a04 0x1 0x0 0x0 0x96f8a18 0x1 0x0 0x0 0x96f8ea8 0x1 0x0 0x0 0x96f9044 0x1 0x0 0x0 0x96f904c 0x1 0x0 0x0 0x96f9054 0x1 0x0 0x0 0x96f905c 0x1 0x0 0x0 0x96f910c 0x2 0x0 0x0 0x96f9204 0x1 0x0 0x0 0x96f920c 0x1 0x0 0x0 0x96f9238 0x1 0x0 0x0 0x96f9240 0x1 0x0 0x0 0x96f926c 0x1 0x0 0x0 0x96f9394 0x1 0x0 0x0 0x96f939c 0x1 0x0 0x0 0x96f9704 0x1 0x0 0x0 0x96f970c 0x1 0x0 0x0 0x9130100 0x3 0x0 0x0 0x9170100 0x3 0x0 0x0 0x91dd100 0x4 0x0 0x0 0x91df100 0x1 0x0 0x0 0x610110 0x5 0x0 0x0 0x9230010 0x1 0x0 0x0 0x9230020 0x1 0x0 0x0 0x9230030 0x1 0x0 0x0 0x9230040 0x1 0x0 0x0 0x92b0010 0x1 0x0 0x0 0x92b0020 0x1 0x0 0x0 0x92b0030 0x1 0x0 0x0 0x92b0040 0x1 0x0 0x0 0x9232050 0x1 0x0 0x0 0x923605c 0x2 0x0 0x0 0x92360a0 0x1 0x0 0x0 0x923a018 0x2 0x0 0x0 0x92b2050 0x1 0x0 0x0 0x92b605c 0x2 0x0 0x0 0x92b60a0 0x1 0x0 0x0 0x92ba018 0x2 0x0 0x0 0x9222404 0x2 0x0 0x0 0x9222410 0x1 0x0 0x0 0x9238004 0x1 0x0 0x0 0x9238014 0x1 0x0 0x0 0x923805c 0x1 0x0 0x0 0x923a014 0x1 0x0 0x0 0x92a2404 0x2 0x0 0x0 0x92a2410 0x1 0x0 0x0 0x92b8004 0x1 0x0 0x0 0x92b8014 0x1 0x0 0x0 0x92b805c 0x1 0x0 0x0 0x92ba014 0x1 0x0 0x0 0x905000c 0x1 0x0 0x0 0x9050948 0x1 0x0 0x0 0x9050078 0x1 0x0 0x0 0x9050008 0x1 0x0 0x0 0x9084878 0x1 0x0 0x0 0x9050950 0x1 0x0 0x0 0x90c2884 0x1 0x0>;
	};

	link_list@3 {
		qcom,data-sink = "sram";
		qcom,curr-link-list = <0x3>;
		qcom,link-list = <0x0 0xb2c4520 0x1 0x0 0x0 0xb2c1020 0x2 0x0 0x0 0xb2c1030 0x1 0x0 0x0 0xb2c1200 0x1 0x0 0x0 0xb2c1214 0x1 0x0 0x0 0xb2c1228 0x1 0x0 0x0 0xb2c123c 0x1 0x0 0x0 0xb2c1250 0x1 0x0 0x0 0xb2c1204 0x1 0x0 0x0 0xb2c1218 0x1 0x0 0x0 0xb2c122c 0x1 0x0 0x0 0xb2c1240 0x1 0x0 0x0 0xb2c1254 0x1 0x0 0x0 0xb2c1208 0x1 0x0 0x0 0xb2c121c 0x1 0x0 0x0 0xb2c1230 0x1 0x0 0x0 0xb2c1244 0x1 0x0 0x0 0xb2c1258 0x1 0x0 0x0 0xb2c4510 0x2 0x0 0x0 0xb2c0010 0x2 0x0 0x0 0xb2c0900 0x2 0x0 0x0 0x4082028 0x1 0x0 0x0 0x18a00c 0x1 0x0 0x0 0x4080044 0x1 0x0 0x0 0x4080304 0x1 0x0 0x0 0x41a802c 0x1 0x0 0x0 0x4200010 0x3 0x0 0x0 0x4200030 0x1 0x0 0x0 0x4200038 0x1 0x0 0x0 0x4200040 0x1 0x0 0x0 0x4200048 0x1 0x0 0x0 0x42000d0 0x1 0x0 0x0 0x4200210 0x1 0x0 0x0 0x4200230 0x1 0x0 0x0 0x4200250 0x1 0x0 0x0 0x4200270 0x1 0x0 0x0 0x4200290 0x1 0x0 0x0 0x42002b0 0x1 0x0 0x0 0x4200208 0x1 0x0 0x0 0x4200228 0x1 0x0 0x0 0x4200248 0x1 0x0 0x0 0x4200268 0x1 0x0 0x0 0x4200288 0x1 0x0 0x0 0x42002a8 0x1 0x0 0x0 0x420020c 0x1 0x0 0x0 0x420022c 0x1 0x0 0x0 0x420024c 0x1 0x0 0x0 0x420026c 0x1 0x0 0x0 0x420028c 0x1 0x0 0x0 0x42002ac 0x1 0x0 0x0 0x4200400 0x3 0x0 0x0 0x4200d04 0x1 0x0 0x0 0x4130010 0x3 0x0 0x0 0x4130210 0x1 0x0 0x0 0x4130230 0x1 0x0 0x0 0x4130250 0x1 0x0 0x0 0x4130270 0x1 0x0 0x0 0x4130290 0x1 0x0 0x0 0x41302b0 0x1 0x0 0x0 0x4130208 0x1 0x0 0x0 0x4130228 0x1 0x0 0x0 0x4130248 0x1 0x0 0x0 0x4130268 0x1 0x0 0x0 0x4130288 0x1 0x0 0x0 0x41302a8 0x1 0x0 0x0 0x413020c 0x1 0x0 0x0 0x413022c 0x1 0x0 0x0 0x413024c 0x1 0x0 0x0 0x413026c 0x1 0x0 0x0 0x413028c 0x1 0x0 0x0 0x41302ac 0x1 0x0 0x0 0x4130400 0x3 0x0 0x0 0xb254520 0x1 0x0 0x0 0xb251020 0x2 0x0 0x0 0xb251030 0x1 0x0 0x0 0xb251200 0x1 0x0 0x0 0xb251214 0x1 0x0 0x0 0xb251228 0x1 0x0 0x0 0xb25123c 0x1 0x0 0x0 0xb251250 0x1 0x0 0x0 0xb251204 0x1 0x0 0x0 0xb251218 0x1 0x0 0x0 0xb25122c 0x1 0x0 0x0 0xb251240 0x1 0x0 0x0 0xb251254 0x1 0x0 0x0 0xb251208 0x1 0x0 0x0 0xb25121c 0x1 0x0 0x0 0xb251230 0x1 0x0 0x0 0xb251244 0x1 0x0 0x0 0xb251258 0x1 0x0 0x0 0xb254510 0x2 0x0 0x0 0xb250010 0x2 0x0 0x0 0xb250900 0x2 0x0 0x0 0x3002028 0x1 0x0 0x0 0x3500010 0x3 0x0 0x0 0x3500030 0x1 0x0 0x0 0x3500038 0x1 0x0 0x0 0x3500040 0x1 0x0 0x0 0x3500048 0x1 0x0 0x0 0x35000d0 0x1 0x0 0x0 0x3500210 0x1 0x0 0x0 0x3500230 0x1 0x0 0x0 0x3500250 0x1 0x0 0x0 0x3500270 0x1 0x0 0x0 0x3500290 0x1 0x0 0x0 0x35002b0 0x1 0x0 0x0 0x3500208 0x1 0x0 0x0 0x3500228 0x1 0x0 0x0 0x3500248 0x1 0x0 0x0 0x3500268 0x1 0x0 0x0 0x3500288 0x1 0x0 0x0 0x35002a8 0x1 0x0 0x0 0x350020c 0x1 0x0 0x0 0x350022c 0x1 0x0 0x0 0x350024c 0x1 0x0 0x0 0x350026c 0x1 0x0 0x0 0x350028c 0x1 0x0 0x0 0x35002ac 0x1 0x0 0x0 0x3500400 0x3 0x0 0x0 0x3500d04 0x1 0x0 0x0 0x30b0010 0x3 0x0 0x0 0x30b0210 0x1 0x0 0x0 0x30b0230 0x1 0x0 0x0 0x30b0250 0x1 0x0 0x0 0x30b0270 0x1 0x0 0x0 0x30b0290 0x1 0x0 0x0 0x30b02b0 0x1 0x0 0x0 0x30b0208 0x1 0x0 0x0 0x30b0228 0x1 0x0 0x0 0x30b0248 0x1 0x0 0x0 0x30b0268 0x1 0x0 0x0 0x30b0288 0x1 0x0 0x0 0x30b02a8 0x1 0x0 0x0 0x30b020c 0x1 0x0 0x0 0x30b022c 0x1 0x0 0x0 0x30b024c 0x1 0x0 0x0 0x30b026c 0x1 0x0 0x0 0x30b028c 0x1 0x0 0x0 0x30b02ac 0x1 0x0 0x0 0x30b0400 0x3 0x0 0x0 0xb2b4520 0x1 0x0 0x0 0xb2b1020 0x2 0x0 0x0 0xb2b1030 0x1 0x0 0x0 0xb2b1200 0x1 0x0 0x0 0xb2b1214 0x1 0x0 0x0 0xb2b1228 0x1 0x0 0x0 0xb2b123c 0x1 0x0 0x0 0xb2b1250 0x1 0x0 0x0 0xb2b1204 0x1 0x0 0x0 0xb2b1218 0x1 0x0 0x0 0xb2b122c 0x1 0x0 0x0 0xb2b1240 0x1 0x0 0x0 0xb2b1254 0x1 0x0 0x0 0xb2b1208 0x1 0x0 0x0 0xb2b121c 0x1 0x0 0x0 0xb2b1230 0x1 0x0 0x0 0xb2b1244 0x1 0x0 0x0 0xb2b1258 0x1 0x0 0x0 0xb2b4510 0x2 0x0 0x0 0xb2b0010 0x1 0x0 0x0 0xb2b0900 0x1 0x0 0x0 0xa302028 0x1 0x0 0x0 0xa0a4010 0x3 0x0 0x0 0xa0a4030 0x1 0x0 0x0 0xa0a4038 0x1 0x0 0x0 0xa0a4040 0x2 0x0 0x0 0xa0a40d0 0x1 0x0 0x0 0xa0a4210 0x1 0x0 0x0 0xa0a4230 0x1 0x0 0x0 0xa0a4250 0x1 0x0 0x0 0xa0a4270 0x1 0x0 0x0 0xa0a4290 0x1 0x0 0x0 0xa0a42b0 0x1 0x0 0x0 0xa0a4208 0x1 0x0 0x0 0xa0a4228 0x1 0x0 0x0 0xa0a4248 0x1 0x0 0x0 0xa0a4268 0x1 0x0 0x0 0xa0a4288 0x1 0x0 0x0 0xa0a42a8 0x1 0x0 0x0 0xa0a420c 0x1 0x0 0x0 0xa0a422c 0x1 0x0 0x0 0xa0a424c 0x1 0x0 0x0 0xa0a426c 0x1 0x0 0x0 0xa0a428c 0x1 0x0 0x0 0xa0a42ac 0x1 0x0 0x0 0xa0a4400 0x2 0x0 0x0 0xa0a4d04 0x1 0x0 0x0 0xa3b0010 0x3 0x0 0x0 0xa3b0210 0x1 0x0 0x0 0xa3b0230 0x1 0x0 0x0 0xa3b0250 0x1 0x0 0x0 0xa3b0270 0x1 0x0 0x0 0xa3b0290 0x1 0x0 0x0 0xa3b02b0 0x1 0x0 0x0 0xa3b0208 0x1 0x0 0x0 0xa3b0228 0x1 0x0 0x0 0xa3b0248 0x1 0x0 0x0 0xa3b0268 0x1 0x0 0x0 0xa3b0288 0x1 0x0 0x0 0xa3b02a8 0x1 0x0 0x0 0xa3b020c 0x1 0x0 0x0 0xa3b022c 0x1 0x0 0x0 0xa3b024c 0x1 0x0 0x0 0xa3b026c 0x1 0x0 0x0 0xa3b028c 0x1 0x0 0x0 0xa3b02ac 0x1 0x0 0x0 0xa3b0400 0x3 0x0 0x0 0x3500d00 0x3 0x0 0x0 0x3500d10 0x4 0x0 0x0 0x3500fb0 0x4 0x0 0x0 0x3501250 0x4 0x0 0x0 0x35014f0 0x4 0x0 0x0 0x3501790 0x4 0x0 0x0 0x3501a30 0x4 0x0 0x0 0x3503d44 0x4 0x0 0x0 0x35000d0 0x3 0x0 0x0 0x3500100 0x1 0x0 0x0 0x3500d3c 0x1 0x0 0x0 0xa0a40d0 0x3 0x0 0x0 0xa0a4100 0x1 0x0 0x0 0xa0a4d3c 0x1 0x0 0x0 0xa0a7d44 0x4 0x0 0x0 0xa0a4d00 0x3 0x0 0x0 0x8a02028 0x1 0x0 0x0 0x8b00000 0x1 0x0 0x0 0x8b00004 0x1 0x0 0x0 0x8b00010 0x1 0x0 0x0 0x8b00014 0x1 0x0 0x0 0x8b00018 0x1 0x0 0x0 0x8b0001c 0x1 0x0 0x0 0x8b00020 0x1 0x0 0x0 0x8b00024 0x1 0x0 0x0 0x8b00028 0x1 0x0 0x0 0x8b0002c 0x1 0x0 0x0 0x8b00030 0x1 0x0 0x0 0x8b00034 0x1 0x0 0x0 0x8b00038 0x1 0x0 0x0 0x8b0003c 0x1 0x0 0x0 0x8b00040 0x1 0x0 0x0 0x8b00044 0x1 0x0 0x0 0x8b00048 0x1 0x0 0x0 0x8b000d0 0x1 0x0 0x0 0x8b000d8 0x1 0x0 0x0 0x8b00100 0x1 0x0 0x0 0x8b00104 0x1 0x0 0x0 0x8b00108 0x1 0x0 0x0 0x8b00200 0x1 0x0 0x0 0x8b00204 0x1 0x0 0x0 0x8b00224 0x1 0x0 0x0 0x8b00244 0x1 0x0 0x0 0x8b00264 0x1 0x0 0x0 0x8b00284 0x1 0x0 0x0 0x8b002a4 0x1 0x0 0x0 0x8b00208 0x1 0x0 0x0 0x8b00228 0x1 0x0 0x0 0x8b00248 0x1 0x0 0x0 0x8b00268 0x1 0x0 0x0 0x8b00288 0x1 0x0 0x0 0x8b002a8 0x1 0x0 0x0 0x8b0020c 0x1 0x0 0x0 0x8b0022c 0x1 0x0 0x0 0x8b0024c 0x1 0x0 0x0 0x8b0026c 0x1 0x0 0x0 0x8b0028c 0x1 0x0 0x0 0x8b002ac 0x1 0x0 0x0 0x8b00210 0x1 0x0 0x0 0x8b00230 0x1 0x0 0x0 0x8b00250 0x1 0x0 0x0 0x8b00270 0x1 0x0 0x0 0x8b00290 0x1 0x0 0x0 0x8b002b0 0x1 0x0 0x0 0x8b00400 0x1 0x0 0x0 0x8b00404 0x1 0x0 0x0 0x8b00408 0x1 0x0 0x0 0x8b00460 0x1 0x0 0x0 0x8b00464 0x1 0x0 0x0 0x8b004a0 0x1 0x0 0x0 0x8b004a4 0x1 0x0 0x0 0x8b004a8 0x1 0x0 0x0 0x8b004ac 0x1 0x0 0x0 0x8b004b0 0x1 0x0 0x0 0x8b004b4 0x1 0x0 0x0 0x8b004b8 0x1 0x0 0x0 0x8ab0000 0x1 0x0 0x0 0x8ab0004 0x1 0x0 0x0 0x8ab0010 0x1 0x0 0x0 0x8ab0014 0x1 0x0 0x0 0x8ab0018 0x1 0x0 0x0 0x8ab00d0 0x1 0x0 0x0 0x8ab00d8 0x1 0x0 0x0 0x8ab0100 0x1 0x0 0x0 0x8ab0104 0x1 0x0 0x0 0x8ab0108 0x1 0x0 0x0 0x8ab0200 0x1 0x0 0x0 0x8ab0204 0x1 0x0 0x0 0x8ab0224 0x1 0x0 0x0 0x8ab0244 0x1 0x0 0x0 0x8ab0264 0x1 0x0 0x0 0x8ab0284 0x1 0x0 0x0 0x8ab02a4 0x1 0x0 0x0 0x8ab0208 0x1 0x0 0x0 0x8ab0228 0x1 0x0 0x0 0x8ab0248 0x1 0x0 0x0 0x8ab0268 0x1 0x0 0x0 0x8ab0288 0x1 0x0 0x0 0x8ab02a8 0x1 0x0 0x0 0x8ab020c 0x1 0x0 0x0 0x8ab022c 0x1 0x0 0x0 0x8ab024c 0x1 0x0 0x0 0x8ab026c 0x1 0x0 0x0 0x8ab028c 0x1 0x0 0x0 0x8ab02ac 0x1 0x0 0x0 0x8ab0210 0x1 0x0 0x0 0x8ab0230 0x1 0x0 0x0 0x8ab0250 0x1 0x0 0x0 0x8ab0270 0x1 0x0 0x0 0x8ab0290 0x1 0x0 0x0 0x8ab02b0 0x1 0x0 0x0 0x8ab0400 0x1 0x0 0x0 0x8ab0404 0x1 0x0 0x0 0x8ab0408 0x1 0x0 0x0 0x8ab0460 0x1 0x0 0x0 0x8ab0464 0x1 0x0 0x0 0x8ab04a0 0x1 0x0 0x0 0x8ab04a4 0x1 0x0 0x0 0x8ab04a8 0x1 0x0 0x0 0x8ab04ac 0x1 0x0 0x0 0x8ab04b0 0x1 0x0 0x0 0x8ab04b4 0x1 0x0 0x0 0x8ab04b8 0x1 0x0 0x0 0xaa10504 0x1 0x0 0x0 0xaa10508 0x1 0x0 0x0 0xaa10510 0x1 0x0 0x0 0xaa10520 0x1 0x0 0x0 0xaa10524 0x1 0x0 0x0 0xaa10528 0x1 0x0 0x0 0xaa1052c 0x1 0x0 0x0 0xaa10530 0x1 0x0 0x0 0xaa10534 0x1 0x0 0x0 0xaa10538 0x1 0x0 0x0 0xaa1053c 0x1 0x0 0x0 0xaa10300 0x1 0x0 0x0 0xaa10010 0x1 0x0 0x0 0xaa10020 0x1 0x0>;
	};

	link_list1 {
		qcom,curr-link-list = <0xff>;
	};

	link_list2 {
		qcom,curr-link-list = <0xff>;
	};

	link_list3 {
		qcom,curr-link-list = <0xff>;
	};
};

&firmware {

	android {

		vbmeta {
			compatible = "android,vbmeta";
			parts = "vbmeta,boot,system,vendor,dtbo,product,odm,prism,optics,vbmeta_system,vendor_boot,recovery,abl,xbl,tz,hyp";
		};
	};
};

